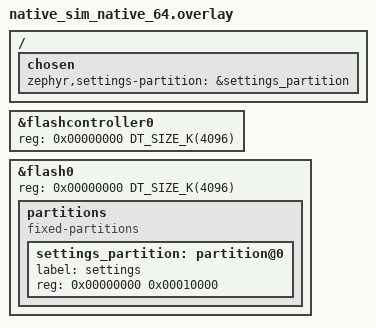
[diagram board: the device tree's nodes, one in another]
/ {
    chosen {
        zephyr,settings-partition = &settings_partition;
    };
};

&flashcontroller0 {
    reg = <0x00000000 DT_SIZE_K(4096)>;
};

&flash0 {
    reg = <0x00000000 DT_SIZE_K(4096)>;
    partitions {
      compatible = "fixed-partitions";
      #address-cells = <1>;
      #size-cells = <1>;

      settings_partition: partition@0 {
          label = "settings";
          reg = <0x00000000 0x00010000>;
      };
    };
};
